VERSION ""

NS_ :

BS_:

BU_:

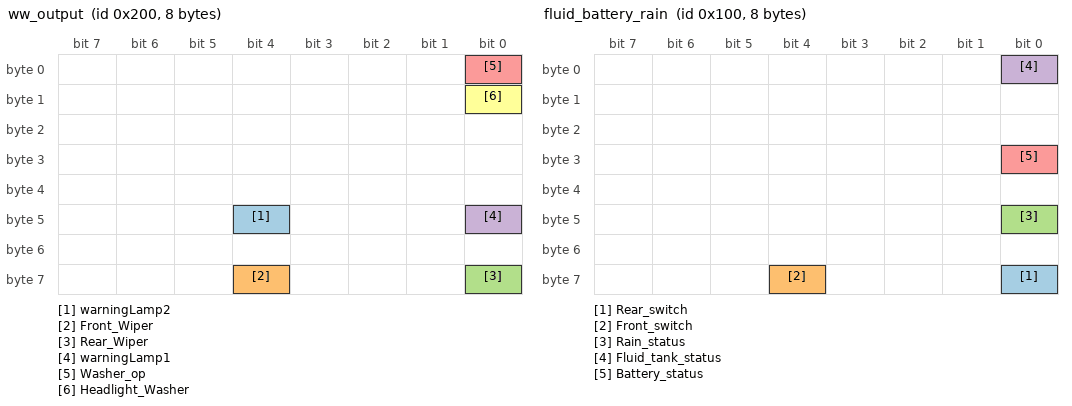
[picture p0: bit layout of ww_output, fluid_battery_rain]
BO_ 512 ww_output: 8 Vector__XXX
 SG_ warningLamp2 : 44|1@1+ (1,0) [0|1] "" Vector__XXX
 SG_ Front_Wiper : 60|1@1+ (1,0) [0|1] "" Vector__XXX
 SG_ Rear_Wiper : 56|1@1+ (1,0) [0|1] "" Vector__XXX
 SG_ warningLamp1 : 40|1@1+ (1,0) [0|1] "" Vector__XXX
 SG_ Washer_op : 0|1@1+ (1,0) [0|1] "" Vector__XXX
 SG_ Headlight_Washer : 8|1@1+ (1,0) [0|1] "" Vector__XXX

BO_ 256 fluid_battery_rain: 8 Vector__XXX
 SG_ Rear_switch : 56|1@1+ (1,0) [0|1] "" Vector__XXX
 SG_ Front_switch : 60|1@1+ (1,0) [0|1] "" Vector__XXX
 SG_ Rain_status : 40|1@1+ (1,0) [0|1] "" Vector__XXX
 SG_ Fluid_tank_status : 0|1@1+ (1,0) [0|1] "" Vector__XXX
 SG_ Battery_status : 24|1@1+ (1,0) [0|1] "" Vector__XXX
